# HDSC_HC32M423 register map
Vendor: HDSC Co.,Ltd.; Series: ARMCM4; File version: 1.0
CPU: CM4 r0p1, little endian, MPU, FPU, 4 interrupt priority bits
Registers are 32-bit, read-write, reset 0x0 unless marked. A register's access mark holds for its fields unless they carry their own. Offsets are from the block's base; lines under a group give offsets from that group; [hi:lo] are bit positions; {n}, {i} and the like mark numbered series; 'fields as' and 'values as' point back to an identical list; <NAME> marks a mode.

## Memory map
0x00000240 ICG size 0x20
0x40010000 CTC size 0xC
0x40010400 EFM size 0x283
0x40010800 AOS size 0x94
0x40015000 TMRA1 size 0x144
0x40015400 TMRA2 size 0x144
0x40015800 TMRA3 size 0x148
0x40015C00 TMRA4 size 0x148
0x40017000 TMR4 size 0xE6
0x40017C00 EMB size 0x3C
0x4001C000 SPI size 0x1C
0x4001D000 USART1 size 0x10
0x4001D400 USART2 size 0x10
0x40021000 USART3 size 0x10
0x40021400 USART4 size 0x10
0x40024000 TMR01 size 0x18 — desc TMR0
0x40024400 TMR02 size 0x18 — desc TMR0
0x40025000 TMRB size 0x150
0x40030000 ADC size 0x64
0x40048400 FCM size 0x24
0x40049000 WDT size 0xC
0x40049400 SWDT size 0xC
0x4004A000 CMP1 size 0x6 — desc CMP
0x4004A010 CMP2 size 0x6
0x4004A020 CMP3 size 0x6
0x4004A100 DAC size 0xE
0x4004E000 I2C size 0x34
0x40050400 CRC size 0x100
0x40051000 INTC size 0x2A8
0x40052000 DCU size 0x1C
0x40053000 DMA size 0x110
0x40053800 GPIO size 0x5F
0x40054000 EMU size 0x42
0x40054100 RMU size 0x2
0x40054400 CMU size 0x4D
0xE0042000 DBGC size 0x1C

## ADC
Base 0x40030000
0x00 STR 8-bit
  [0] STRT
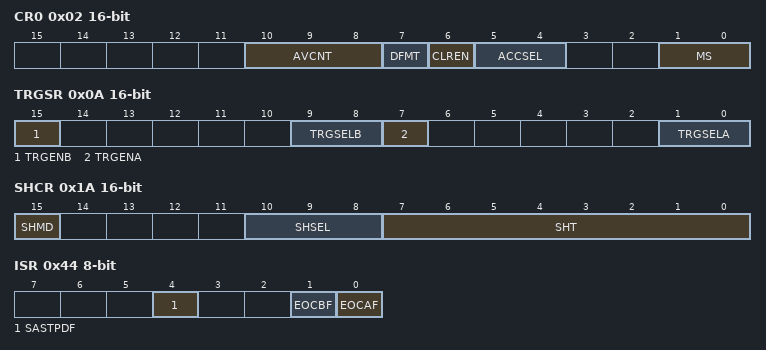
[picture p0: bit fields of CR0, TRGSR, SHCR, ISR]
0x02 CR0 16-bit
  [10:8] AVCNT, [7] DFMT, [6] CLREN, [5:4] ACCSEL, [1:0] MS
0x04 CR1 16-bit
  [2] RSCHSEL
0x0A TRGSR 16-bit
  [15] TRGENB, [9:8] TRGSELB, [7] TRGENA, [1:0] TRGSELA
0x0C CHSELRA0 16-bit
  [9:0] CHSELA
0x10 CHSELRB0 16-bit
  [9:0] CHSELB
0x14 AVCHSELR0 16-bit
  [9:0] AVCHSEL
0x18 EXCHSELR 8-bit
  [0] EXCHSEL
0x1A SHCR 16-bit
  [15] SHMD, [10:8] SHSEL, [7:0] SHT
{0x20+i} SSTR{i} 8-bit reset 0xB (i=0..9)
0x44 ISR 8-bit ro
  [4] SASTPDF, [1] EOCBF, [0] EOCAF
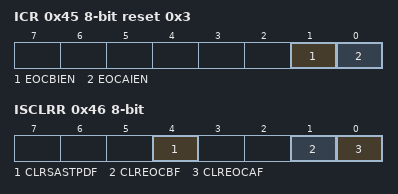
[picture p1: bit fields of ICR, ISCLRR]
0x45 ICR 8-bit reset 0x3
  [1] EOCBIEN, [0] EOCAIEN
0x46 ISCLRR 8-bit wo
  [4] CLRSASTPDF, [1] CLREOCBF, [0] CLREOCAF
{0x50+2i} DR{i} 16-bit ro (i=0..9)

## AOS
Base 0x40010800
0x00 INTC_STRGCR wo
  [0] STRG
0x20 TMR00_HTSSR reset 0x1FF
  [8:0] TRGSEL
0x24 TMR01_HTSSR reset 0x1FF
  [8:0] TRGSEL
0x40 TMRA0_HTSSR reset 0x1FF
  [8:0] TRGSEL
0x44 TMRA1_HTSSR reset 0x1FF
  [8:0] TRGSEL
0x50 TMRB_HTSSR reset 0x1FF
  [8:0] TRGSEL
0x60 ADC_ITRGSELR0 reset 0x1FF
  [8:0] TRGSEL
0x64 ADC_ITRGSELR1 reset 0x1FF
  [8:0] TRGSEL
{0x80+4i} DMA{i}_TRGSEL reset 0x1FF (i=0..3)
  [8:0] TRGSEL
0x90 DCU_TRGSEL reset 0x1FF
  [8:0] TRGSEL

## CMP1 — desc CMP
Base 0x4004A000
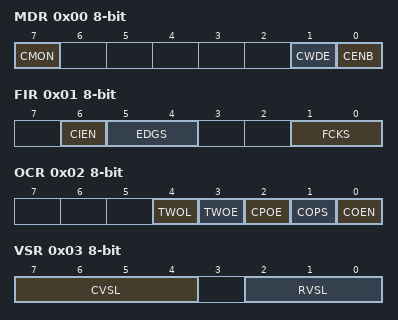
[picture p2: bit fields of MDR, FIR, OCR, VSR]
0x00 MDR 8-bit (reset mask 0x81)
  [7] CMON ro, [1] CWDE, [0] CENB
0x01 FIR 8-bit
  [6] CIEN, [5:4] EDGS, [1:0] FCKS
0x02 OCR 8-bit
  [4] TWOL, [3] TWOE, [2] CPOE, [1] COPS, [0] COEN
0x03 VSR 8-bit
  [7:4] CVSL, [2:0] RVSL
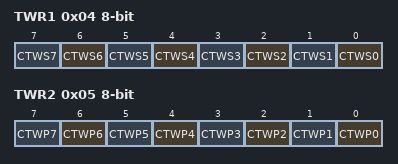
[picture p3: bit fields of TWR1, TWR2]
0x04 TWR1 8-bit
  [n] CTWS{n} (n=0..7)
0x05 TWR2 8-bit
  [n] CTWP{n} (n=0..7)

## CMP2
Base 0x4004A010
Registers as CMP1; these are added or differ:
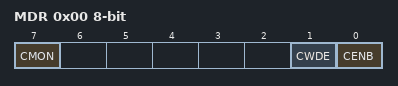
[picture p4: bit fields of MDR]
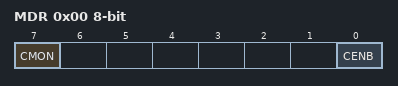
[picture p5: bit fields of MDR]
0x00 MDR 8-bit
  [7] CMON ro, [1] CWDE, [0] CENB

## CMP3
Base 0x4004A020
Registers as CMP1; these are added or differ:
0x00 MDR 8-bit
  [7] CMON ro, [0] CENB

## CMU
Base 0x40054400
0x00 ADCKSEL 8-bit
  [2:0] ADCKSEL
0x04 XTALSTDSR 8-bit
  [0] XTALSTDF
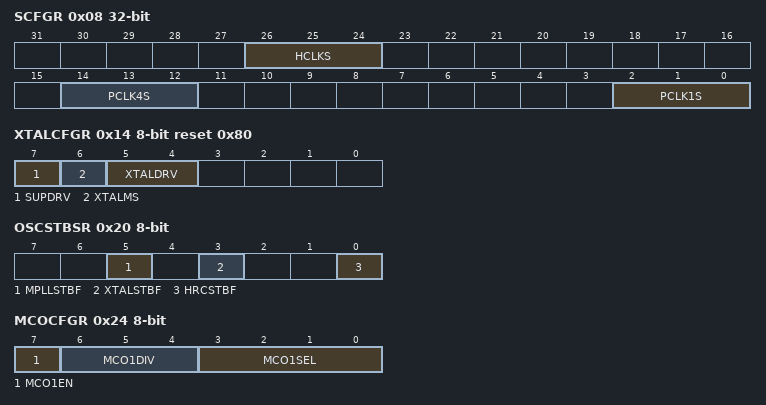
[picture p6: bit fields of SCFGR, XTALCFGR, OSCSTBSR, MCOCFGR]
0x08 SCFGR
  [26:24] HCLKS, [14:12] PCLK4S, [2:0] PCLK1S
0x0C CKSWR 8-bit
  [2:0] CKSW
0x10 XTALCR 8-bit reset 0x1
  [0] XTALSTP
0x14 XTALCFGR 8-bit reset 0x80
  [7] SUPDRV, [6] XTALMS, [5:4] XTALDRV
0x15 XTALSTBCR 8-bit
  [2:0] XTALSTB
0x18 HRCCR 8-bit
  [0] HRCSTP
0x1C HRCCFGR 8-bit
  [3:0] HRCFREQS
0x20 OSCSTBSR 8-bit ro
  [5] MPLLSTBF, [3] XTALSTBF, [0] HRCSTBF
0x24 MCOCFGR 8-bit
  [7] MCO1EN, [6:4] MCO1DIV, [3:0] MCO1SEL
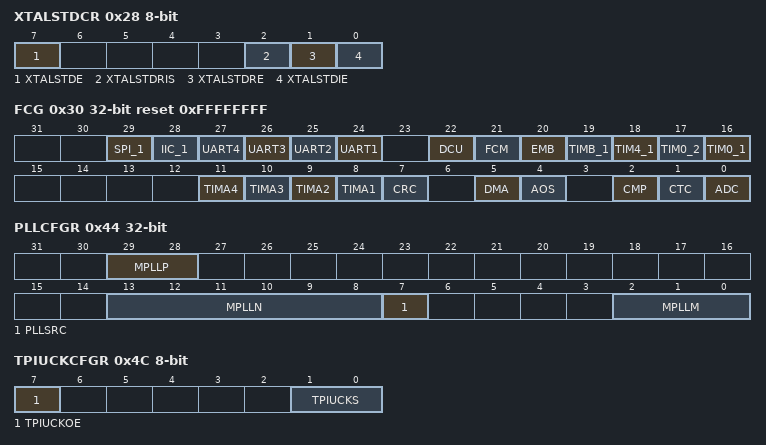
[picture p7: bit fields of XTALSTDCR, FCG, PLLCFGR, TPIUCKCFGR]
0x28 XTALSTDCR 8-bit
  [7] XTALSTDE, [2] XTALSTDRIS, [1] XTALSTDRE, [0] XTALSTDIE
0x30 FCG reset 0xFFFFFFFF
  [29] SPI_1, [28] IIC_1, [n+23] UART{n} (n=1..4), [22] DCU, [21] FCM, [20] EMB, [19] TIMB_1, [18] TIM4_1, [17] TIM0_2, [16] TIM0_1, [n+7] TIMA{n} (n=1..4), [7] CRC, [5] DMA, [4] AOS, [2] CMP, [1] CTC, [0] ADC
0x3C LRCCR 8-bit
  [0] LRCSTP
0x40 MRCCR 8-bit
  [0] MRCSTP
0x44 PLLCFGR
  [29:28] MPLLP, [13:8] MPLLN, [7] PLLSRC, [2:0] MPLLM
0x48 PLLCR 8-bit reset 0x1
  [0] MPLLOFF
0x4C TPIUCKCFGR 8-bit
  [7] TPIUCKOE, [1:0] TPIUCKS
